# FE310 register map
Vendor: SiFive
Registers are 32-bit, read-write, reset 0x0 unless marked. A register's access mark holds for its fields unless they carry their own. Offsets are from the block's base; lines under a group give offsets from that group; [hi:lo] are bit positions; {n}, {i} and the like mark numbered series; 'fields as' and 'values as' point back to an identical list; <NAME> marks a mode.

## Memory map
0x02000000 CLINT — Coreplex Local Interrupts
0x0C000000 PLIC — Platform Level Interrupt Control
0x10000000 WDOG — Watchdog
0x10000000 RTC — Watchdog
0x10000000 AONCLK — Always-On Clock Configuration
0x10000000 BACKUP — Backup Registers
0x10000000 PMU
0x10008000 PRCI — Power Reset Clock Interrupts
0x10010000 OTP — One Time Programmable Memory
0x10012000 GPIO0 — General Purpose Input Output
0x10013000 UART0 — Universal Asynchronous Receiver Transmitter
0x10014000 QSPI0 — Quad Serial Peripheral Interface
0x10015000 PWM0 — 8-bit timer with 4 cmp
0x10016000 I2C0 — Inter-Integrated Circuit Master Interface (FE310-G002 only)
0x10023000 UART1
0x10024000 QSPI1
0x10025000 PWM1
0x10034000 QSPI2
0x10035000 PWM2

## Interrupts
1 WATCHDOG (WDOG)
2 RTC
3 UART0
4 UART1
5 QSPI0
6 QSPI1
7 QSPI2
8 GPIO0
{n+8} GPIO{n} (GPIO0) (n=1..31)
40 PWM0CMP0 (PWM0)
41 PWM0CMP1 (PWM0)
42 PWM0CMP2 (PWM0)
43 PWM0CMP3 (PWM0)
44 PWM1CMP0 (PWM1)
45 PWM1CMP1 (PWM1)
46 PWM1CMP2 (PWM1)
47 PWM1CMP3 (PWM1)
48 PWM2CMP0 (PWM2)
49 PWM2CMP1 (PWM2)
50 PWM2CMP2 (PWM2)
51 PWM2CMP3 (PWM2)
52 I2C0

## CLINT — Coreplex Local Interrupts
Base 0x02000000
0x00 msip range 0..1 — Hart 0 software interrupt register
0x4000 mtimecmp — Hart 0 time comparator register
0x4004 mtimecmph — Hart 0 time comparator register
0xBFF8 mtime — Timer register
0xBFFC mtimeh — Timer register

## PLIC — Platform Level Interrupt Control
Base 0x0C000000
{0x0+4i} priority[{i}] (i=0..52) — Interrupt Priority Register
  [2:0] priority
    0=P0 (Priority 0 (never interrupt)); {v}=P{v} (Priority {v}) (v=1..7)
{0x1000+4i} pending[{i}] (i=0..1) — Interrupt Pending Register
{0x2000+4i} enable[{i}] (i=0..1) — Interrupt Enable Register
0x200000 threshold — Priority Threshold Register
  [2:0] priority
    {v}=P{v} (Allow interrupts with priority > {v}) (v=0..6); 7=P7 (Mask all interrupts)
0x200004 claim — Claim/Complete Register

## WDOG — Watchdog
Base 0x10000000
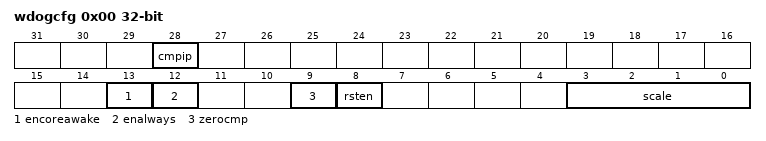
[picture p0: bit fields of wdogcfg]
0x00 wdogcfg — Watchdog Configuration Register
  [28] cmpip, [13] encoreawake, [12] enalways, [9] zerocmp, [8] rsten, [3:0] scale
0x08 wdogcount — Watchdog Counter Register
0x10 wdogs — Watchdog Scaled Counter Register
0x18 wdogfeed — Watchdog Feed Register
0x1C wdogkey wo reset 0x51F15E — Watchdog Key Register
0x20 wdogcmp — Watchdog Compare Register
  [15:0] value

## RTC — Watchdog
Base 0x10000000
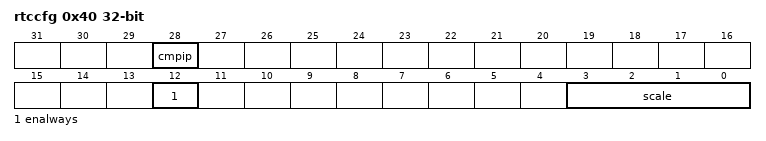
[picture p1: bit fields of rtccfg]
0x40 rtccfg — RTC Configuration Register
  [28] cmpip, [12] enalways, [3:0] scale
0x48 rtclo — RTC Counter Low Register
0x4C rtchi — RTC Counter High Register
  [15:0] value
0x50 rtcs — RTC Scaled Counter Register
0x60 rtccmp — RTC Compare Register

## AONCLK — Always-On Clock Configuration
Base 0x10000000
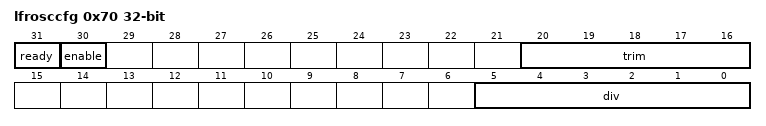
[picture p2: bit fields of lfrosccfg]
0x70 lfrosccfg — AON Clock Configuration Register
  [31] ready, [30] enable, [20:16] trim, [5:0] div

## BACKUP — Backup Registers
Base 0x10000000
{0x80+4i} backup[{i}] (i=0..15)

## PMU
Base 0x10000000
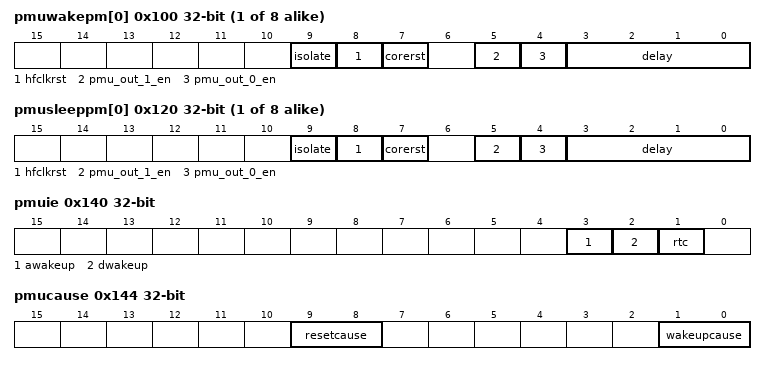
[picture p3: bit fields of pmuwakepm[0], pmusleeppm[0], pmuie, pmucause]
{0x100+4i} pmuwakepm[{i}] (i=0..7) — PMU Wake Program Memory
  [9] isolate, [8] hfclkrst, [7] corerst, [5] pmu_out_1_en, [4] pmu_out_0_en, [3:0] delay
{0x120+4i} pmusleeppm[{i}] (i=0..7) — PMU Sleep Program Memory
  fields as pmuwakepm[0]
0x140 pmuie — PMU Interrupt Enable Register
  [3] awakeup, [2] dwakeup, [1] rtc
0x144 pmucause
  [9:8] resetcause
    0=Power-on reset; 1=External reset; 2=Watchdog reset
  [1:0] wakeupcause
    0=Reset wakeup; 1=RTC (RTC wakeup); 2=Digital input wakeup
0x148 pmusleep wo
  [0] sleep
0x14C pmukey

## PRCI — Power Reset Clock Interrupts
Base 0x10008000
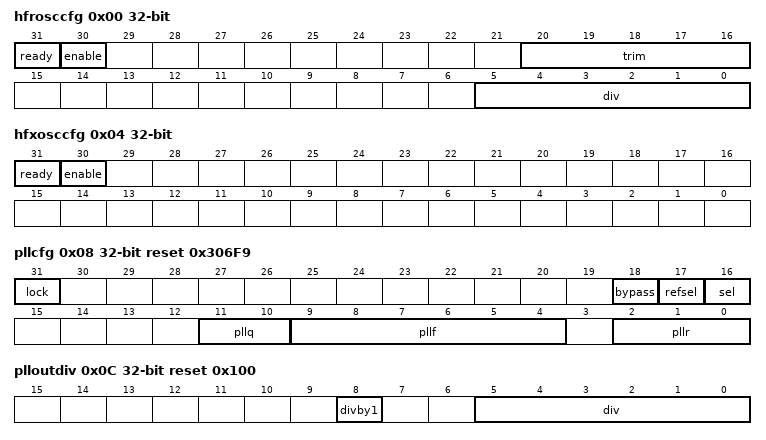
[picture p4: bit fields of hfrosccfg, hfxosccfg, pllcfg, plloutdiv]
0x00 hfrosccfg — Clock Configuration Register
  [31] ready, [30] enable, [20:16] trim, [5:0] div
0x04 hfxosccfg — Clock Configuration Register
  [31] ready, [30] enable
0x08 pllcfg reset 0x306F9 — PLL Configuration Register
  [31] lock
  [18] bypass
  [17] refsel
  [16] sel
  [11:10] pllq
    1=Q2; 2=Q4; 3=Q8
  [9:4] pllf
  [2:0] pllr
    {v}=R{v+1} (v=0..3)
0x0C plloutdiv reset 0x100 — PLL Divider Register
  [8] divby1, [5:0] div
0x10 coreclkcfg — Clock Configuration Register
